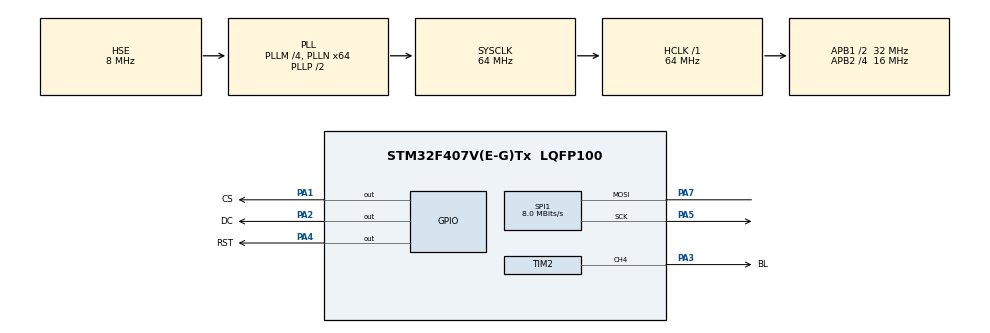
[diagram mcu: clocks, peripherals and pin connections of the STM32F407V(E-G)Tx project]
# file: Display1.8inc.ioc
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Mcu.Family=STM32F4
Mcu.Name=STM32F407V(E-G)Tx
Mcu.Package=LQFP100
NVIC.PriorityGroup=NVIC_PRIORITYGROUP_0
PA1.GPIO_Label=CS
PA1.Signal=GPIO_Output
PA2.GPIO_Label=DC
PA2.Signal=GPIO_Output
PA3.GPIO_Label=BL
PA3.Signal=S_TIM2_CH4
PA4.GPIO_Label=RST
PA4.Signal=GPIO_Output
PA5.Mode=Simplex_Bidirectional_Master
PA5.Signal=SPI1_SCK
PA7.Mode=Simplex_Bidirectional_Master
PA7.Signal=SPI1_MOSI
PH0-OSC_IN.Mode=HSE-External-Oscillator
PH0-OSC_IN.Signal=RCC_OSC_IN
PH1-OSC_OUT.Mode=HSE-External-Oscillator
PH1-OSC_OUT.Signal=RCC_OSC_OUT
ProjectManager.HeapSize=0x200
ProjectManager.StackSize=0x400
ProjectManager.TargetToolchain=STM32CubeIDE
RCC.48MHZClocksFreq_Value=18285714.285714287
RCC.AHBFreq_Value=64000000
RCC.APB1CLKDivider=RCC_HCLK_DIV2
RCC.APB1Freq_Value=32000000
RCC.APB1TimFreq_Value=64000000
RCC.APB2CLKDivider=RCC_HCLK_DIV4
RCC.APB2Freq_Value=16000000
RCC.APB2TimFreq_Value=32000000
RCC.CortexFreq_Value=64000000
RCC.HCLKFreq_Value=64000000
RCC.HSE_VALUE=8000000
RCC.HSI_VALUE=16000000
RCC.LSE_VALUE=32768
RCC.PLLM=4
RCC.PLLN=64
RCC.PLLQ=7
RCC.PLLSourceVirtual=RCC_PLLSOURCE_HSE
RCC.SYSCLKFreq_VALUE=64000000
RCC.SYSCLKSource=RCC_SYSCLKSOURCE_PLLCLK
RCC.VCOOutputFreq_Value=128000000
SH.S_TIM2_CH4.0=TIM2_CH4,PWM Generation4 CH4
SPI1.CalculateBaudRate=8.0 MBits/s
SPI1.Direction=SPI_DIRECTION_1LINE
SPI1.Mode=SPI_MODE_MASTER
SPI1.VirtualType=VM_MASTER
TIM2.AutoReloadPreload=TIM_AUTORELOAD_PRELOAD_ENABLE
TIM2.Channel-PWM\ Generation4\ CH4=TIM_CHANNEL_4
TIM2.Period=1000-1
TIM2.Prescaler=300-1
VP_TIM2_VS_ClockSourceINT.Mode=Internal
board=STM32F407G-DISC1

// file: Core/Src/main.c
/* USER CODE BEGIN Header */
/**
  ******************************************************************************
  * @file           : main.c
  * @brief          : Main program body
  ******************************************************************************
  * @attention
  *
  * Copyright (c) 2024 STMicroelectronics.
  * All rights reserved.
  *
  * This software is licensed under terms that can be found in the LICENSE file
  * in the root directory of this software component.
  * If no LICENSE file comes with this software, it is provided AS-IS.
  *
  ******************************************************************************
  */
/* USER CODE END Header */
#include "main.h"
#include "spi.h"
#include "tim.h"
#include "gpio.h"

/* USER CODE BEGIN Includes */
#include "GUI_Paint.h"
#include "fonts.h"
#include "LCD_Test.h"

/* USER CODE END Includes */

void SystemClock_Config(void);

int main(void)
{

  /* MCU Configuration--------------------------------------------------------*/

  /* Reset of all peripherals, Initializes the Flash interface and the Systick. */
  HAL_Init();

  /* Configure the system clock */
  SystemClock_Config();

  /* Initialize all configured peripherals */
  MX_GPIO_Init();
  MX_SPI1_Init();
  MX_TIM2_Init();
  /* USER CODE BEGIN 2 */
  LCD_1in8_test();
  /* USER CODE END 2 */

  /* Infinite loop */
  while (1)
  {

  }
}

void SystemClock_Config(void)
{
  RCC_OscInitTypeDef RCC_OscInitStruct = {0};
  RCC_ClkInitTypeDef RCC_ClkInitStruct = {0};

  /** Configure the main internal regulator output voltage
  */
  __HAL_RCC_PWR_CLK_ENABLE();
  __HAL_PWR_VOLTAGESCALING_CONFIG(PWR_REGULATOR_VOLTAGE_SCALE1);

  /** Initializes the RCC Oscillators according to the specified parameters
  * in the RCC_OscInitTypeDef structure.
  */
  RCC_OscInitStruct.OscillatorType = RCC_OSCILLATORTYPE_HSE;
  RCC_OscInitStruct.HSEState = RCC_HSE_ON;
  RCC_OscInitStruct.PLL.PLLState = RCC_PLL_ON;
  RCC_OscInitStruct.PLL.PLLSource = RCC_PLLSOURCE_HSE;
  RCC_OscInitStruct.PLL.PLLM = 4;
  RCC_OscInitStruct.PLL.PLLN = 64;
  RCC_OscInitStruct.PLL.PLLP = RCC_PLLP_DIV2;
  RCC_OscInitStruct.PLL.PLLQ = 7;
  if (HAL_RCC_OscConfig(&RCC_OscInitStruct) != HAL_OK)
  {
    Error_Handler();
  }

  /** Initializes the CPU, AHB and APB buses clocks
  */
  RCC_ClkInitStruct.ClockType = RCC_CLOCKTYPE_HCLK|RCC_CLOCKTYPE_SYSCLK
                              |RCC_CLOCKTYPE_PCLK1|RCC_CLOCKTYPE_PCLK2;
  RCC_ClkInitStruct.SYSCLKSource = RCC_SYSCLKSOURCE_PLLCLK;
  RCC_ClkInitStruct.AHBCLKDivider = RCC_SYSCLK_DIV1;
  RCC_ClkInitStruct.APB1CLKDivider = RCC_HCLK_DIV2;
  RCC_ClkInitStruct.APB2CLKDivider = RCC_HCLK_DIV4;

  if (HAL_RCC_ClockConfig(&RCC_ClkInitStruct, FLASH_LATENCY_2) != HAL_OK)
  {
    Error_Handler();
  }
}

void Error_Handler(void)
{
  __disable_irq();
  while (1)
  {
  }
}
